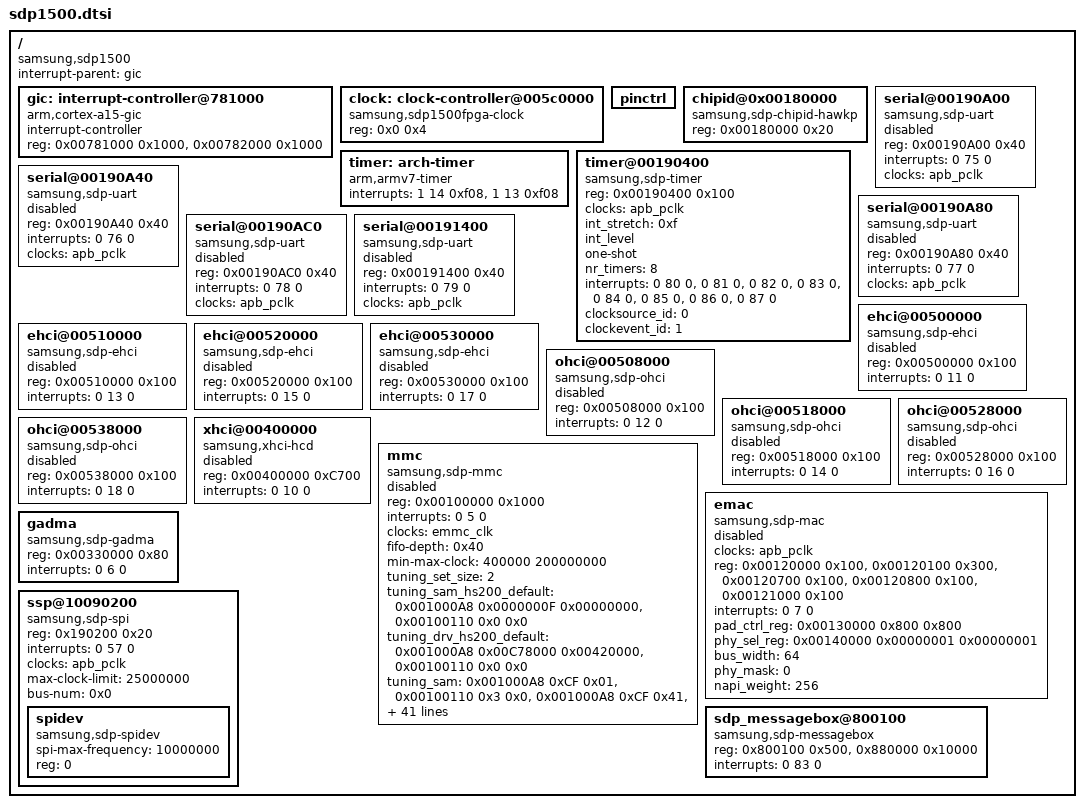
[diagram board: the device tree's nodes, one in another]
/*
 * Copyright (C) 2015 Samsung Electronics Co.Ltd
 *
 * This program is free software; you can redistribute it and/or modify
 * it under the terms of the GNU General Public License version 2 as
 * published by the Free Software Foundation.
 */

/include/ "sdp.dtsi"
/include/ "sdp1500-clocks.dtsi"
/include/ "sdp1500-pinctrl.dtsi"

/ {
	compatible = "samsung,sdp1500";

	interrupt-parent = <&gic>;

	gic: interrupt-controller@781000 {
		compatible = "arm,cortex-a15-gic";
		interrupt-controller;
		#interrupt-cells = <3>;
		reg = <0x00781000 0x1000>, <0x00782000 0x1000>;
	};

	clock:clock-controller@005c0000 {
		compatible = "samsung,sdp1500fpga-clock";
		//reg = <0x005c0000 0x200>;
		reg = <0x0 0x4>;//for FPGA
		#clock-cells = <1>;
	};

	pinctrl{
		status = "okay";
	};

	chipid@0x00180000 {
                compatible = "samsung,sdp-chipid-hawkp";
                reg = <0x00180000 0x20>;
        };

	timer: arch-timer {
		compatible = "arm,armv7-timer";
		interrupts = <1 14 0xf08>,
				<1 13 0xf08>;
	};

	timer@00190400 {
		compatible = "samsung,sdp-timer";
		reg = <0x00190400 0x100>;
		clocks = <&apb_pclk>;
		clock-names = "apb_pclk";
		int_stretch = <0xf>;
		int_level;
		one-shot;
		nr_timers = <8>;
		interrupts = <0 80 0>, <0 81 0>, <0 82 0>, <0 83 0>, <0 84 0>, <0 85 0>, <0 86 0>, <0 87 0>;
		clocksource_id = <0>;
		clockevent_id = <1>;
	};


	serial@00190A00 {
		compatible = "samsung,sdp-uart";
		reg = <0x00190A00 0x40>;
		interrupts = <0 75 0>;
		clocks = <&apb_pclk>;
		clock-names = "apb_pclk";
		status = "disabled";
	};

	serial@00190A40 {
		compatible = "samsung,sdp-uart";
		reg = <0x00190A40 0x40>;
		interrupts = <0 76 0>;
		clocks = <&apb_pclk>;
		clock-names = "apb_pclk";
		//irq-affinity = <2>;
		status = "disabled";
	};

	serial@00190A80 {
		compatible = "samsung,sdp-uart";
		reg = <0x00190A80 0x40>;
		interrupts = <0 77 0>;
		clocks = <&apb_pclk>;
		clock-names = "apb_pclk";
		//irq-affinity = <2>;
		status = "disabled";
	};

	serial@00190AC0 {
		compatible = "samsung,sdp-uart";
		reg = <0x00190AC0 0x40>;
		interrupts = <0 78 0>;
		clocks = <&apb_pclk>;
		clock-names = "apb_pclk";
		//irq-affinity = <2>;
		status = "disabled";
	};

	serial@00191400 {
		compatible = "samsung,sdp-uart";
		reg = <0x00191400 0x40>;
		interrupts = <0 79 0>;
		clocks = <&apb_pclk>;
		clock-names = "apb_pclk";
		//irq-affinity = <2>;
		status = "disabled";
	};


	ehci@00500000 {
		compatible = "samsung,sdp-ehci", "usb-ehci";
		reg = <0x00500000 0x100>;
		interrupts = <0 11 0>;
		status = "disabled";
	};

	ehci@00510000 {
		compatible = "samsung,sdp-ehci", "usb-ehci";
		reg = <0x00510000 0x100>;
		interrupts = <0 13 0>;
		status = "disabled";
	};

	ehci@00520000 {
		compatible = "samsung,sdp-ehci", "usb-ehci";
		reg = <0x00520000 0x100>;
		interrupts = <0 15 0>;
		status = "disabled";
	};

	ehci@00530000 {
		compatible = "samsung,sdp-ehci", "usb-ehci";
		reg = <0x00530000 0x100>;
		interrupts = <0 17 0>;
		status = "disabled";
	};

	ohci@00508000 {
		compatible = "samsung,sdp-ohci", "usb-ohci";
		reg = <0x00508000 0x100>;
		interrupts = <0 12 0>;
		status = "disabled";
	};

	ohci@00518000 {
		compatible = "samsung,sdp-ohci", "usb-ohci";
		reg = <0x00518000 0x100>;
		interrupts = <0 14 0>;
		status = "disabled";
	};

	ohci@00528000 {
		compatible = "samsung,sdp-ohci", "usb-ohci";
		reg = <0x00528000 0x100>;
		interrupts = <0 16 0>;
		status = "disabled";
	};

	ohci@00538000 {
		compatible = "samsung,sdp-ohci", "usb-ohci";
		reg = <0x00538000 0x100>;
		interrupts = <0 18 0>;
		status = "disabled";
	};

	
	xhci@00400000 {
		compatible = "samsung,xhci-hcd", "usb-xhci";
		reg = <0x00400000 0xC700>;
		interrupts = <0 10 0>;
		status = "disabled";
	};

	mmc {
		compatible = "samsung,sdp-mmc";
		reg = <0x00100000 0x1000>;
		interrupts = <0 5 0>;
		clocks = <&emmc_clk>;
		clock-names = "emmc_clk";
		fifo-depth = <0x40>;
		min-max-clock = <400000 200000000>;

		//initregs = <0x00130000 0x00000003 0x00000003>,/* 33bit Accesss setting */
		//			<0x001000A8 0x00C7800F 0x00040000>,/* low speed delay */
		//			<0x00100188 0x000003FF 0x000000BC>;/* read dqs delay(47step EVT1 150MHz) */

		tuning_set_size = <2>;

		tuning_sam_hs200_default = <0x001000A8 0x0000000F 0x00000000>, <0x00100110 0x0 0x0>;
		tuning_drv_hs200_default = <0x001000A8 0x00C78000 0x00420000>, <0x00100110 0x0 0x0>;
		tuning_sam =
					<0x001000A8 0xCF 0x01>, <0x00100110 0x3 0x0>,
					<0x001000A8 0xCF 0x41>, <0x00100110 0x3 0x0>,
					<0x001000A8 0xCF 0x02>, <0x00100110 0x3 0x0>,
					<0x001000A8 0xCF 0x42>, <0x00100110 0x3 0x0>,
					<0x001000A8 0xCF 0x03>, <0x00100110 0x3 0x0>,
					<0x001000A8 0xCF 0x43>, <0x00100110 0x3 0x0>,
					<0x001000A8 0xCF 0x04>, <0x00100110 0x3 0x0>,
					<0x001000A8 0xCF 0x44>, <0x00100110 0x3 0x0>,
					<0x001000A8 0xCF 0x05>, <0x00100110 0x3 0x0>,
					<0x001000A8 0xCF 0x45>, <0x00100110 0x3 0x0>,
					<0x001000A8 0xCF 0x06>, <0x00100110 0x3 0x0>,
					<0x001000A8 0xCF 0x46>, <0x00100110 0x3 0x0>,
					<0x001000A8 0xCF 0x07>, <0x00100110 0x3 0x0>,
					<0x001000A8 0xCF 0x47>, <0x00100110 0x3 0x0>,
					<0x001000A8 0xCF 0x08>, <0x00100110 0x3 0x0>,
					<0x001000A8 0xCF 0x48>, <0x00100110 0x3 0x0>;

		tuning_sam_hs400_default = <0x001000A8 0x000000CF 0x00000041>, <0x00100110 0x0 0x0>;
		tuning_drv_hs400_default = <0x001000A8 0x00C78000 0x00410000>, <0x00100110 0x0 0x0>;
		tuning_sam_hs400 =
					<0x001000A8 0xCF 0x01>, <0x00100110 0x3 0x0>,
					<0x001000A8 0xCF 0x41>, <0x00100110 0x3 0x0>,
					<0x001000A8 0xCF 0x81>, <0x00100110 0x3 0x0>,
					<0x001000A8 0xCF 0x02>, <0x00100110 0x3 0x0>,
					<0x001000A8 0xCF 0x42>, <0x00100110 0x3 0x0>,
					<0x001000A8 0xCF 0x82>, <0x00100110 0x3 0x0>,
					<0x001000A8 0xCF 0x03>, <0x00100110 0x3 0x0>,
					<0x001000A8 0xCF 0x43>, <0x00100110 0x3 0x0>,
					<0x001000A8 0xCF 0x83>, <0x00100110 0x3 0x0>,
					<0x001000A8 0xCF 0x04>, <0x00100110 0x3 0x0>,
					<0x001000A8 0xCF 0x44>, <0x00100110 0x3 0x0>,
					<0x001000A8 0xCF 0x84>, <0x00100110 0x3 0x0>;

		bus-width = <0x8>;
//		force-pio-mode;
		hw-reset;

		/* Host Caps */
		non-removable;
//		bus-width-test;
		highspeed;
//		sdr104;
//		ddr50;
		hs200;
		hs200-tuning;
		hs400;

		status = "disabled";
	};


	emac {
		compatible = "samsung,sdp-mac";
		clocks = <&apb_pclk>;
		clock-names = "emac_clk";
		reg = <0x00120000 0x100>,
			<0x00120100 0x300>,
			<0x00120700 0x100>,
			<0x00120800 0x100>,
			<0x00121000 0x100>;
		interrupts = <0 7 0>;
		pad_ctrl_reg = <0x00130000 0x800 0x800>;/* select SRAM for MAC */
		phy_sel_reg = <0x00140000 0x00000001 0x00000001>;		/* select RGMII register */
		bus_width = <64>;
		phy_mask = <0>;
		napi_weight = <256>;

		status = "disabled";
	};

	gadma {
		//status = "disabled";
		compatible = "samsung,sdp-gadma";
		reg = <0x00330000 0x80>;
		interrupts = <0 6 0>;
		//clocks = <&dma_clk>;
		//clock-names = "dma_clk";
	};



         ssp@10090200 {
                 status = "okay";
                 compatible = "samsung,sdp-spi";
                 reg = <0x190200 0x20>;
                 interrupts = <0 57 0>;
                 clocks = <&apb_pclk>;
                 clock-names = "apb_pclk";
 
                 #address-cells = <1>;
                 #size-cells = <0>;
 
                 max-clock-limit = <25000000>;
                 bus-num = <0x0>;
 
                 //cs-gpios = <&gpio10 5 0>;/* o_SMC_ADDR[1] port (P10.5) Ctrl reg */
 
                 spidev {
                         #address-cells = <1>;
                         #size-cells = <1>;
                         compatible = "samsung,sdp-spidev";
                         spi-max-frequency = <10000000>;
                         reg = <0>;
                 };
 /*
                 flash: w25x40@0 {
                         #address-cells = <1>;
                         #size-cells = <1>;
                         compatible = "winbond,w25x40";
                         spi-max-frequency = <10000000>;
                         reg = <0>;
 
                         partition@0 {
                                 label = "ucode";
                                 reg = <0x0 0x80000>;
                         };
                 };
 */
	};

	sdp_messagebox@800100 {
		compatible = "samsung,sdp-messagebox";
		reg = <0x800100 0x500>, <0x880000 0x10000>;
		interrupts = <0 83 0>;
	};

};
